# RL6955_IP_SVD register map
Vendor: Realtek
Registers are 32-bit, read-write, reset 0x0 unless marked. A register's access mark holds for its fields unless they carry their own. Offsets are from the block's base; [hi:lo] are bit positions; {n}, {i} and the like mark numbered series.

## PMC
Base 0x41000300
0x00 REG_WAK_STATUS0 ro
  [29:0] wak_evt0_sta_29_0 — Acoording chip_arch spec
0x04 REG_WAK_STATUS1 ro
  [29:0] wak_evt0_sta_59_30 — Acoording chip_arch spec
0x08 REG_WAK_MASK0_NP
  [29:0] wak_np_imr_29_0 — 1:mask enable for wake NP, this used to wak pmc
0x0C REG_WAK_MASK1_NP
  [29:0] wak_np_imr_59_30 — 1:mask enable for wake NP, this used to wak pmc
0x10 REG_WAK_MASK0_AP
  [29:0] wak_ap_imr_29_0 — 1:mask enable for wake AP
0x14 REG_WAK_MASK1_AP
  [29:0] wak_ap_imr_59_30 — 1:mask enable for wake AP
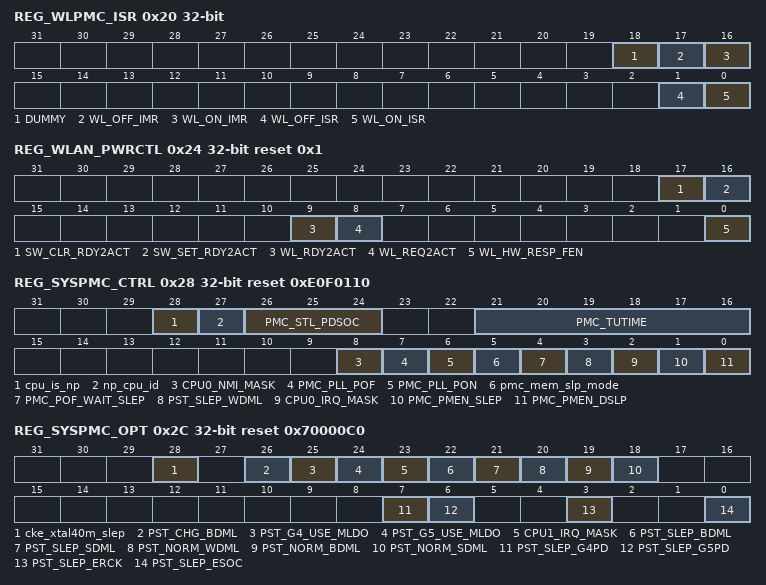
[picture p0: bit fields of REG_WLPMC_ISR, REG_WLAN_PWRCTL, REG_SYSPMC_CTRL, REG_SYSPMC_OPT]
0x20 REG_WLPMC_ISR access per field
  [18] DUMMY rw, [17] WL_OFF_IMR rw, [16] WL_ON_IMR rw, [1] WL_OFF_ISR ro, [0] WL_ON_ISR ro
0x24 REG_WLAN_PWRCTL access per field reset 0x1
  [17] SW_CLR_RDY2ACT rw — System infrom WLAN ready to active
  [16] SW_SET_RDY2ACT rw
  [9] WL_RDY2ACT ro — System infrom WLAN ready to active
  [8] WL_REQ2ACT ro
  [0] WL_HW_RESP_FEN rw — 1: enable HW auto response
0x28 REG_SYSPMC_CTRL access per field reset 0xE0F0110
  [28] cpu_is_np ro — This bit indicate if current cpu who read this bit is used as NP 1: is NP 0: is AP
  [27] np_cpu_id rw — 0:cpu0(km4tz) used as NP, pmc will enable it after system wake 1:cpu1(km4ns) used as NP.
  [26:24] PMC_STL_PDSOC rw — timer wait for core power power-cut power stable . 000:8us * 2^1 001:8us * 2^2 010:8us * 2^3 // 64us 011:8us * 2^4 100:8us * 2^5 101:8us * 2^6 110:8us * 2^7 // pon default 111:8us * 2^8
  [21:16] PMC_TUTIME rw — PMC timeunit setting, in cycles of osc2M e.g, default 0xF, timeunit = 8us
  [8] CPU0_NMI_MASK rw — Interrupt mask for CPU0 NVIC[0]: plfm1 reset 1.mask interrupt 0:enable interrupt
  [7] PMC_PLL_POF rw — 1: Request PLL pof by software,plfm and system cpu will auto select to pll path . Which one pll will be active is determined by pst_cksl_sys_cpu and pst_cksl_sys_hperi. This bit auto clear to 0 after by HW PMC Note: HW will pof one pll or two if cpu pll and hperi cpu are different after arbitration with bt .
  [6] PMC_PLL_PON rw — 1: Request PLL pon by software,plfm and system cpu will auto select to pll path . Which one pll will be active is determined by pst_cksl_sys_cpu and pst_cksl_sys_hperi. This bit auto clear to 0 after by HW PMC Note: HW will pon one pll or two if cpu pll and hperi cpu are different
  [5] pmc_mem_slp_mode rw — Select memory parameter option 1: sleep setting 0: normal setting Note:defautl set to sleep setting to save power when snooze
  [4] PMC_POF_WAIT_SLEP rw — 1.when SW set pmen_slep or pmen_dslp , hw pmc will wait cpu0 enter sleep mode , then begin to pof seq 0.Not wait cpu sleep
  [3] PST_SLEP_WDML rw — normal setting for WMAC request Core LDO dummy load selection 1: enable dummy load when PMC enter into sleep mode 0: disable dummy load when PMC enter into sleep mode
  [2] CPU0_IRQ_MASK rw — 1.mask all KM4 interrupt 0:release all KM4 interrupt
  [1] PMC_PMEN_SLEP rw — 1: Request PMC to enter sleep state, auto clear to 0 after PMC finishes
  [0] PMC_PMEN_DSLP rw — 1: Request PMC to enter deep-sleep state, auto clear to 0 after PMC finishes
0x2C REG_SYSPMC_OPT reset 0x70000C0
  [28] cke_xtal40m_slep — when pmc is sleep status, this bit control u_ckg_xtal40m_slep 1:Enable xtal40m_slep 0:Disable Note:when pmc is not sleep, u_ckg_xtal40m_slep will be enabled whether value this bit is Remove to lp_pmc option register
  [26] PST_CHG_BDML — normal setting for BT request Core LDO dummy load selection 1: enable dummy load during BT PMC change to sleep mode / normal mode 0: disable dummy load during BT PMC change to sleep mode / normal mode
  [25] PST_G4_USE_MLDO — 1: G0 pad use MLDO 1.8v IO power 0: G0 pad use external power and can't shutdown by pmc
  [24] PST_G5_USE_MLDO — 1: G1 pad use MLDO 1.8v IO power(psram only) 0: G1 pad use external power and can't shutdown by pmc
  [23] CPU1_IRQ_MASK — 1.mask all CPU1 interrupt 0:release all CPU1 interrupt
  [22] PST_SLEP_BDML — normal setting for BT request Core LDO dummy load selection 1: enable dummy load when PMC enter into sleep mode 0: disable dummy load when PMC enter into sleep mode
  [21] PST_SLEP_SDML — normal setting for system request Core LDO dummy load selection 1: enable dummy load when PMC enter into sleep mode 0: disable dummy load when PMC enter into sleep mode
  [20] PST_NORM_WDML — normal setting for WMAC request Core LDO dummy load selection 1: enable dummy load when PMC enter into normal mode 0: disable dummy load when PMC enter into normal mode
  [19] PST_NORM_BDML — normal setting for BT request Core LDO dummy load selection 1: enable dummy load when PMC enter into normal mode 0: disable dummy load when PMC enter into normal mode
  [18] PST_NORM_SDML — normal setting for system request Core LDO dummy load selection 1: enable dummy load when PMC enter into normal mode 0: disable dummy load when PMC enter into normal mode
  [7] PST_SLEP_G4PD — 1: G0 pad used for 1.8v IO power , and will shutdown when LDO3318 off in slep, when dslp , it will always shutoff 0: G1 pad not used as 1.8v IO power
  [6] PST_SLEP_G5PD — 1: G1 pad used for 1.8v IO power , and will shutdown when LDO3318 off in slep,, when dslp , it will always shutoff 0: G2 pad not used as 1.8v IO power
  [3] PST_SLEP_ERCK — 1: Enable lpon clock when PMC enter into sleep mode 0: Gate lpon clock when PMC enter into sleep mode
  [0] PST_SLEP_ESOC — 1: power enable SOC platform when PMC enter into sleep mode (clock-gating) 0: power off SoC domain when PMC enter into sleep mode (power-gating)
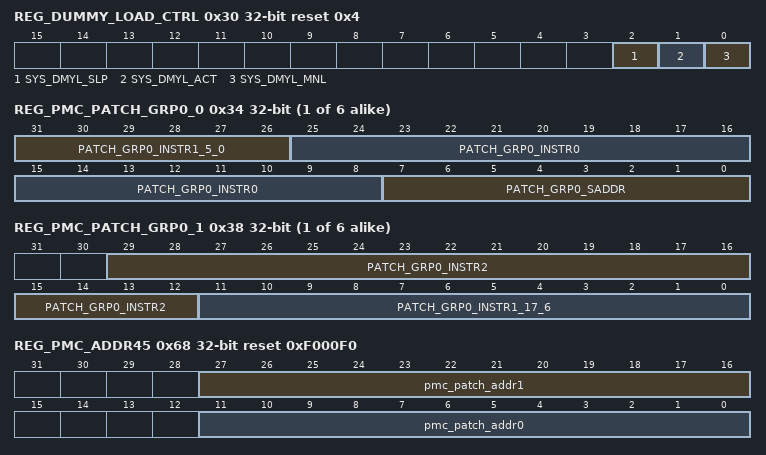
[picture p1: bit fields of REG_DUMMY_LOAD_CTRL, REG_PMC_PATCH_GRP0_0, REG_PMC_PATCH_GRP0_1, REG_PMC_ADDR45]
0x30 REG_DUMMY_LOAD_CTRL reset 0x4
  [2] SYS_DMYL_SLP — this bit means the dummy load state when KM4 is sleep 0: disable 1: enable
  [1] SYS_DMYL_ACT — this bit means the dummy load state when KM4 is active 0: disable 1: enable
  [0] SYS_DMYL_MNL — system use this bit to switch core ldo dummy load control path manually 0: dummy load control is decided by LS/BT/WL PMC arbitration 1: dummy load control is decided by KM4 sleep state
{0x34+8i} REG_PMC_PATCH_GRP{i}_0 (i=0..5)
  [31:26] PATCH_GRP{i}_INSTR1_5_0 — instruction1 of LSYSON PMC patch group{i},bit[5:0]
  [25:8] PATCH_GRP{i}_INSTR0 — instruction0 of LSYSON PMC patch group{i}
  [7:0] PATCH_GRP{i}_SADDR — Start address of the first instruction of LSYSON PMC patch group{i}
{0x38+8i} REG_PMC_PATCH_GRP{i}_1 (i=0..5)
  [29:12] PATCH_GRP{i}_INSTR2 — instruction2 of LSYSON PMC patch group{i}
  [11:0] PATCH_GRP{i}_INSTR1_17_6 — instruction1 of LSYSON PMC patch group{i},bit[17:6]
0x64 REG_PMC_DBG_FLAG
  [7:0] lpon_pmc_flag_pc — PMC will raise a debug flag if hw pmc pc value hit this value
0x68 REG_PMC_ADDR45 reset 0xF000F0
  [27:16] pmc_patch_addr1 — HW used only , these are for pmc patch
  [11:0] pmc_patch_addr0 — HW used only , these are for pmc patch
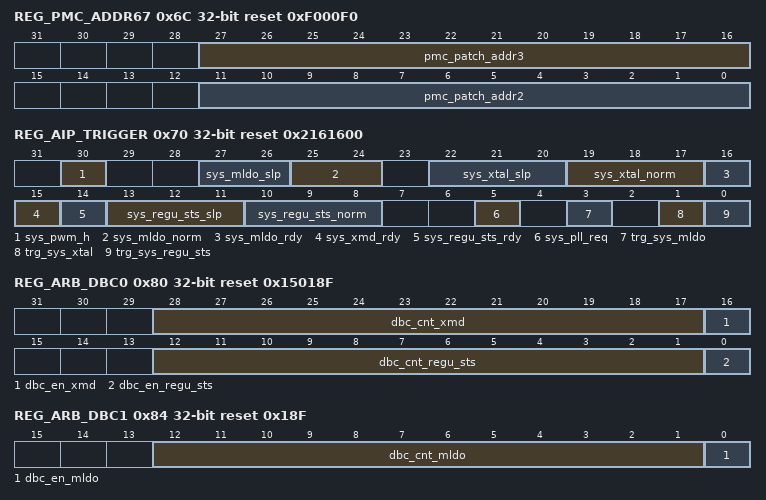
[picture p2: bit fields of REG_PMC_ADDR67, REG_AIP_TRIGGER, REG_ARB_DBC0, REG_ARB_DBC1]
0x6C REG_PMC_ADDR67 reset 0xF000F0
  [27:16] pmc_patch_addr3 — HW used only , these are for pmc patch
  [11:0] pmc_patch_addr2 — HW used only , these are for pmc patch
0x70 REG_AIP_TRIGGER access per field reset 0x2161600
  [30] sys_pwm_h rw — Set pwm in heavy loading by system (SWR current > 200mA) 1:Heavy 0:Light
  [27:26] sys_mldo_slp rw — mem ldo mode slep option 00:off 01:sleep (wo dummy) 10:normal-0 (wi dummy) 10:normal-1 (wo dummy)
  [25:24] sys_mldo_norm rw — mem ldo mode normal option 00:off 01:sleep (wo dummy) 10:normal-0 (wi dummy) 10:normal-1 (wo dummy)
  [22:20] sys_xtal_slp rw — 00: OFF 001: LPS wo 40M 010: LPS with 40M , 011: NORM 100: HP
  [19:17] sys_xtal_norm rw — 00: OFF 001: LPS wo 40M 010: LPS with 40M , 011: NORM 100: HP
  [16] sys_mldo_rdy ro — Ready signal for system mldo req. Software write trg register and sts different value will lead this bit set to 0 by hardware. When HW finish the flow, this bit will be set to 1 by hardware.
  [15] sys_xmd_rdy ro — Ready signal for system xmd state. Software write trg register and sts different value will lead this bit set to 0 by hardware. When HW finish the flow, this bit will be set to 1 by hardware.
  [14] sys_regu_sts_rdy ro — Ready signal for system regu state. Software write trg register and sts different value will lead this bit set to 0 by hardware. When REGU PMC finish the flow, this bit will be set to 1 by hardware.
  [13:11] sys_regu_sts_slp rw — 000: RSVD 001: state1 010: state2 011: state3 100: state4 101: state5 110: state6 111: RSVD
  [10:8] sys_regu_sts_norm rw — 000: RSVD 001: state1 0.7/PC/PFM 010: state2 0.8/PC/PFM 011: state3 0.9/PC/PFM 100: state4 0.9(1.0)/SLP/PFM 101: state5 0.9(1.0)/SLP/PWM 110: state6 0.9(1.0)/NORM/PWM 111: RSVD
  [5] sys_pll_req rw — require pll by system . pll ready can polling 0xA8 SYSTEM_CFG0
  [3] trg_sys_mldo wo
  [1] trg_sys_xtal wo
  [0] trg_sys_regu_sts wo — write 1 to trigger sys_regu_sts_norm value to take effect
0x80 REG_ARB_DBC0 reset 0x15018F
  [28:17] dbc_cnt_xmd — xmd debounce counter , cycle based in OSC4M
  [16] dbc_en_xmd — xtal mode arbit debounce enable 0:disable 1:enable
  [12:1] dbc_cnt_regu_sts — regu sts debounce counter , cycle based in OSC4M for 4M sync to 100K, it must wait 40us for async handshake
  [0] dbc_en_regu_sts — regu sts arbit debounce enable 0:disable 1:enable
0x84 REG_ARB_DBC1 reset 0x18F
  [12:1] dbc_cnt_mldo — mldo debounce counter , cycle based in OSC4M for 4M sync to 100K, it must wait 40us for async handshake
  [0] dbc_en_mldo — mldo arbit debounce enable 0:disable 1:enable
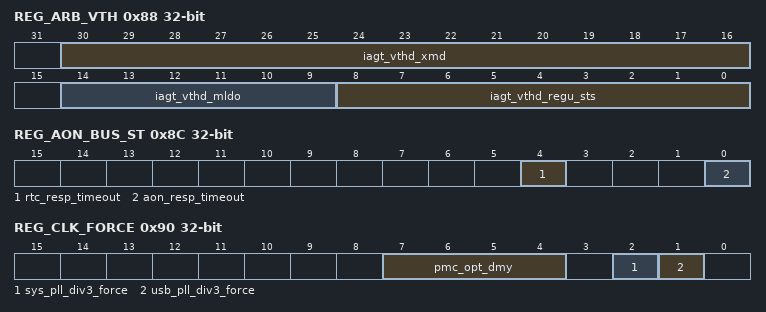
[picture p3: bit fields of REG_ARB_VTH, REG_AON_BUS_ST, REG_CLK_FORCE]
0x88 REG_ARB_VTH
  [30:16] iagt_vthd_xmd — This field used for xmd arb control.
  [14:9] iagt_vthd_mldo — This field used for mldo arb control.
  [8:0] iagt_vthd_regu_sts — This field used for regu sts arb control.
0x8C REG_AON_BUS_ST ro
  [4] rtc_resp_timeout — This flag indicate system access rtc domain timeout , access maybe failed. Active 1. Write 1 will clear the status.
  [0] aon_resp_timeout — This flag indicate system access aon domain timeout , access maybe failed. Active 1. Write 1 will clear the status.
0x90 REG_CLK_FORCE
  [7:4] pmc_opt_dmy — HW used only , these are for pmc patch
  [2] sys_pll_div3_force — force to enable sys pll div3 1:sys pll div3 clock always enable 0:sys pll div3 clock always auto gate when no IP use it
  [1] usb_pll_div3_force — force to enable usb pll div3 1:usb pll div3 clock always enable 0:usb pll div3 clock always auto gate when no IP use it
